# MIMXRT1042 register map
Vendor: nxp.com; File version: 1.0
CPU: CM7 r0p1, little endian, MPU, FPU, VTOR, 4 interrupt priority bits
Registers are 32-bit, read-write, reset 0x0 unless marked. A register's access mark holds for its fields unless they carry their own. Offsets are from the block's base; [hi:lo] are bit positions; 'fields as' and 'values as' point back to an identical list.

## USBNC — USB
Base 0x402E0000; register names take the prefix USBNC_; alternate view of USB
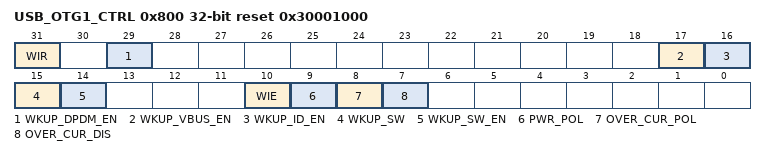
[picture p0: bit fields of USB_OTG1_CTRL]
0x800 USB_OTG1_CTRL reset 0x30001000 — USB OTG1 Control Register
  [31] WIR ro — OTG1 Wake-up Interrupt Request This bit indicates that a wake-up interrupt request is received on the OTG1 port
    0=No wake-up interrupt request received; 1=Wake-up Interrupt Request received
  [29] WKUP_DPDM_EN — Wake-up on DPDM change enable
    0=DPDM changes wake-up to be disabled only when VBUS is 0; 1=(Default) DPDM changes wake-up to be enabled, it is for device only
  [17] WKUP_VBUS_EN — OTG1 wake-up on VBUS change enable
    0=Disable; 1=Enable
  [16] WKUP_ID_EN — OTG1 Wake-up on ID change enable
    0=Disable; 1=Enable
  [15] WKUP_SW — OTG1 Software Wake-up
    0=Inactive; 1=Force wake-up
  [14] WKUP_SW_EN — OTG1 Software Wake-up Enable
    0=Disable; 1=Enable
  [10] WIE — OTG1 Wake-up Interrupt Enable This bit enables or disables the OTG1 wake-up interrupt
    0=Interrupt Disabled; 1=Interrupt Enabled
  [9] PWR_POL — OTG1 Power Polarity This bit should be set according to PMIC Power Pin polarity.
    0=PMIC Power Pin is Low active; 1=PMIC Power Pin is High active
  [8] OVER_CUR_POL — OTG1 Polarity of Overcurrent The polarity of OTG1 port overcurrent event
    0=High active (high on this signal represents an overcurrent condition); 1=Low active (low on this signal represents an overcurrent condition)
  [7] OVER_CUR_DIS — Disable OTG1 Overcurrent Detection
    0=Enables overcurrent detection; 1=Disables overcurrent detection
0x818 USB_OTG1_PHY_CTRL_0 — OTG1 UTMI PHY Control 0 Register
  [31] UTMI_CLK_VLD — Indicating whether OTG1 UTMI PHY clock is valid
    0=Invalid; 1=Valid

## AOI1 — AOI
Base 0x403B4000
Same registers: AOI2 0x403B8000
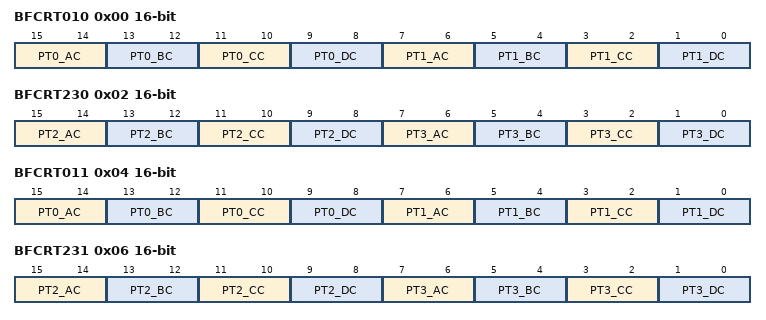
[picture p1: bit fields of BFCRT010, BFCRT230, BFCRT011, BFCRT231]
0x00 BFCRT010 16-bit — Boolean Function Term 0 and 1 Configuration Register for EVENTn
  [15:14] PT0_AC — Product term 0, A input configuration
    0=Force the A input in this product term to a logical zero; 1=Pass the A input in this product term; 2=Complement the A input in this product term; 3=Force the A input in this product term to a logical one
  [13:12] PT0_BC — Product term 0, B input configuration
    0=Force the B input in this product term to a logical zero; 1=Pass the B input in this product term; 2=Complement the B input in this product term; 3=Force the B input in this product term to a logical one
  [11:10] PT0_CC — Product term 0, C input configuration
    0=Force the C input in this product term to a logical zero; 1=Pass the C input in this product term; 2=Complement the C input in this product term; 3=Force the C input in this product term to a logical one
  [9:8] PT0_DC — Product term 0, D input configuration
    0=Force the D input in this product term to a logical zero; 1=Pass the D input in this product term; 2=Complement the D input in this product term; 3=Force the D input in this product term to a logical one
  [7:6] PT1_AC — Product term 1, A input configuration
    values as PT0_AC
  [5:4] PT1_BC — Product term 1, B input configuration
    values as PT0_BC
  [3:2] PT1_CC — Product term 1, C input configuration
    values as PT0_CC
  [1:0] PT1_DC — Product term 1, D input configuration
    values as PT0_DC
0x02 BFCRT230 16-bit — Boolean Function Term 2 and 3 Configuration Register for EVENTn
  [15:14] PT2_AC — Product term 2, A input configuration
    values as BFCRT010.PT0_AC
  [13:12] PT2_BC — Product term 2, B input configuration
    values as BFCRT010.PT0_BC
  [11:10] PT2_CC — Product term 2, C input configuration
    values as BFCRT010.PT0_CC
  [9:8] PT2_DC — Product term 2, D input configuration
    values as BFCRT010.PT0_DC
  [7:6] PT3_AC — Product term 3, A input configuration
    values as BFCRT010.PT0_AC
  [5:4] PT3_BC — Product term 3, B input configuration
    values as BFCRT010.PT0_BC
  [3:2] PT3_CC — Product term 3, C input configuration
    values as BFCRT010.PT0_CC
  [1:0] PT3_DC — Product term 3, D input configuration
    values as BFCRT010.PT0_DC
0x04 BFCRT011 16-bit — Boolean Function Term 0 and 1 Configuration Register for EVENTn
  fields as BFCRT010
0x06 BFCRT231 16-bit — Boolean Function Term 2 and 3 Configuration Register for EVENTn
  fields as BFCRT230
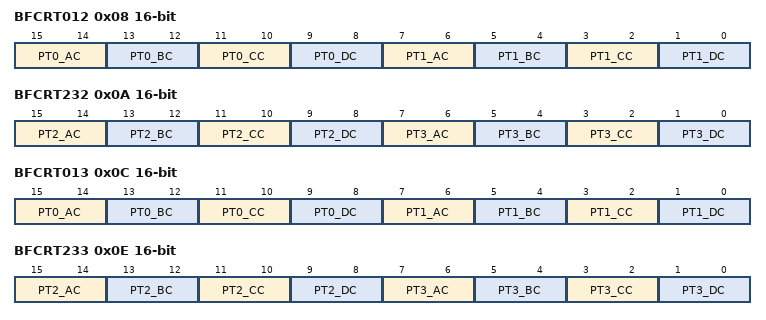
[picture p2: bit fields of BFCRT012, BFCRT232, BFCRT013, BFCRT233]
0x08 BFCRT012 16-bit — Boolean Function Term 0 and 1 Configuration Register for EVENTn
  fields as BFCRT010
0x0A BFCRT232 16-bit — Boolean Function Term 2 and 3 Configuration Register for EVENTn
  fields as BFCRT230
0x0C BFCRT013 16-bit — Boolean Function Term 0 and 1 Configuration Register for EVENTn
  fields as BFCRT010
0x0E BFCRT233 16-bit — Boolean Function Term 2 and 3 Configuration Register for EVENTn
  fields as BFCRT230
